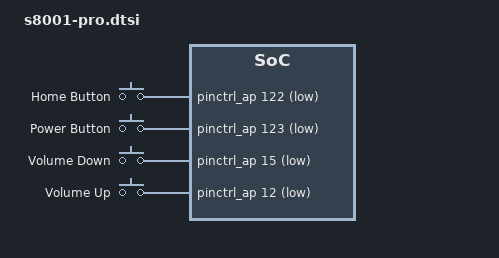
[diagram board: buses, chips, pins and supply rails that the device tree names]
// SPDX-License-Identifier: GPL-2.0+ OR MIT
/*
 * Apple iPad Pro (1st generation) common device tree
 *
 * Copyright (c) 2022, Konrad Dybcio <konradybcio@kernel.org>
 */

#include "s8001.dtsi"
#include "s8001-common.dtsi"
#include <dt-bindings/input/input.h>

/ {
	chassis-type = "tablet";

	gpio-keys {
		compatible = "gpio-keys";

		button-home {
			label = "Home Button";
			gpios = <&pinctrl_ap 122 GPIO_ACTIVE_LOW>;
			linux,code = <KEY_HOMEPAGE>;
			wakeup-source;
		};

		button-power {
			label = "Power Button";
			gpios = <&pinctrl_ap 123 GPIO_ACTIVE_LOW>;
			linux,code = <KEY_POWER>;
			wakeup-source;
		};

		button-voldown {
			label = "Volume Down";
			gpios = <&pinctrl_ap 15 GPIO_ACTIVE_LOW>;
			linux,code = <KEY_VOLUMEDOWN>;
		};

		button-volup {
			label = "Volume Up";
			gpios = <&pinctrl_ap 12 GPIO_ACTIVE_LOW>;
			linux,code = <KEY_VOLUMEUP>;
		};
	};
};
